VERSION "hypothesis-2026-11-23"

NS_ :

BS_:

BU_: ECU CCU TFT ABS Observer

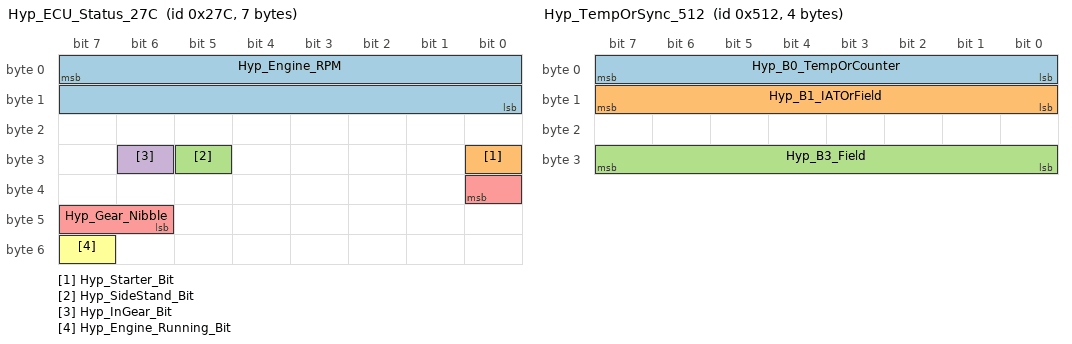
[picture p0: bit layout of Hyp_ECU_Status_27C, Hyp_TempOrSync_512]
BO_ 636 Hyp_ECU_Status_27C: 7 ECU
 SG_ Hyp_Engine_RPM : 7|16@0+ (0.4,0) [0|16000] "rpm" Observer,CCU,TFT
 SG_ Hyp_Starter_Bit : 24|1@0+ (1,0) [0|1] "" Observer
 SG_ Hyp_SideStand_Bit : 29|1@0+ (1,0) [0|1] "" Observer
 SG_ Hyp_InGear_Bit : 30|1@0+ (1,0) [0|1] "" Observer
 SG_ Hyp_Gear_Nibble : 32|3@0+ (1,0) [0|7] "" Observer,CCU,TFT
 SG_ Hyp_Engine_Running_Bit : 55|1@0+ (1,0) [0|1] "" Observer

BO_ 675 Hyp_Unknown_2A3: 8 ECU
 SG_ Hyp_Raw_2A3 : 7|64@0+ (1,0) [0|0] "" Observer

BO_ 899 Hyp_Unknown_383: 8 ECU
 SG_ Hyp_Raw_383 : 7|64@0+ (1,0) [0|0] "" Observer
 SG_ Hyp_BrakeOrFlag_Bit : 35|1@0+ (1,0) [0|1] "" Observer

BO_ 1298 Hyp_TempOrSync_512: 4 ECU
 SG_ Hyp_B0_TempOrCounter : 7|8@0+ (0.625,-30) [-40|215] "C_or_raw" Observer
 SG_ Hyp_B1_IATOrField : 15|8@0+ (0.625,-30) [-40|215] "C_or_raw" Observer
 SG_ Hyp_B3_Field : 31|8@0+ (1,0) [0|255] "" Observer

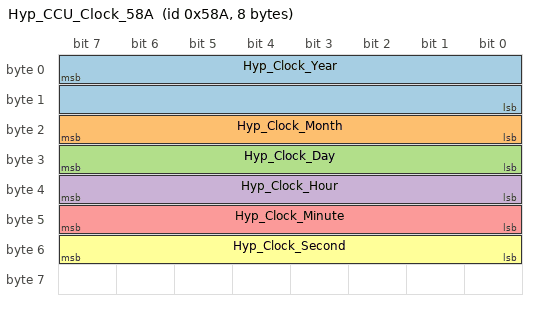
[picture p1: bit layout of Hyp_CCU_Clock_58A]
BO_ 1418 Hyp_CCU_Clock_58A: 8 CCU
 SG_ Hyp_Clock_Year : 7|16@0+ (1,0) [0|9999] "year" Observer,TFT
 SG_ Hyp_Clock_Month : 23|8@0+ (1,0) [0|12] "month" Observer,TFT
 SG_ Hyp_Clock_Day : 31|8@0+ (1,0) [0|31] "day" Observer,TFT
 SG_ Hyp_Clock_Hour : 39|8@0+ (1,0) [0|23] "h" Observer,TFT
 SG_ Hyp_Clock_Minute : 47|8@0+ (1,0) [0|59] "min" Observer,TFT
 SG_ Hyp_Clock_Second : 55|8@0+ (1,0) [0|59] "s" Observer,TFT

BO_ 1419 Hyp_CCU_Info_58B: 8 CCU
 SG_ Hyp_Raw_58B : 7|64@0+ (1,0) [0|0] "" Observer

BO_ 1425 Hyp_CCU_Phone_591: 8 CCU
 SG_ Hyp_Phone_Session : 7|8@0+ (1,0) [0|255] "" Observer,TFT

BO_ 1426 Hyp_CCU_Media_592: 8 CCU
 SG_ Hyp_Media_Status : 7|32@0+ (1,0) [0|0] "" Observer,TFT

BO_ 1428 Hyp_CCU_Notify_594: 8 CCU
 SG_ Hyp_Notify_Mask : 7|32@0+ (1,0) [0|0] "" Observer,TFT

BO_ 1429 Hyp_CCU_Notify_595: 8 CCU
 SG_ Hyp_Notify_Clear : 7|32@0+ (1,0) [0|0] "" Observer,TFT

BO_ 1434 Hyp_CCU_Navi_59A: 8 CCU
 SG_ Hyp_Text_Header : 7|64@0+ (1,0) [0|0] "" Observer,TFT

BO_ 1435 Hyp_CCU_Navi_59B: 8 CCU
 SG_ Hyp_Text_Part1 : 31|40@0+ (1,0) [0|0] "" Observer,TFT

BO_ 1436 Hyp_CCU_Navi_59C: 8 CCU
 SG_ Hyp_Text_Part2 : 15|56@0+ (1,0) [0|0] "" Observer,TFT

BO_ 1437 Hyp_CCU_UI_59D: 8 CCU
 SG_ Hyp_UI_Mode_Mask : 15|8@0+ (1,0) [0|255] "" Observer,TFT

BO_ 1438 Hyp_CCU_UI_59E: 8 CCU
 SG_ Hyp_Raw_59E : 7|64@0+ (1,0) [0|0] "" Observer,TFT

BO_ 1872 Hyp_ECU_750: 8 ECU
 SG_ Hyp_Field_B1B2 : 15|16@0+ (1,0) [0|65535] "" Observer
 SG_ Hyp_Alive_Nibble : 44|5@0+ (1,0) [0|31] "" Observer

BO_ 1873 Hyp_ECU_751: 8 ECU
 SG_ Hyp_B6_Status : 55|8@0+ (1,0) [0|255] "" Observer

BO_ 1877 Hyp_ECU_755: 8 ECU
 SG_ Hyp_B1 : 15|8@0+ (1,0) [0|255] "" Observer
 SG_ Hyp_B3 : 31|8@0+ (1,0) [0|255] "" Observer

BO_ 1878 Hyp_ECU_756: 8 ECU
 SG_ Hyp_B3 : 31|8@0+ (1,0) [0|255] "" Observer
 SG_ Hyp_B5 : 47|8@0+ (1,0) [0|255] "" Observer

BO_ 1879 Hyp_ECU_757: 8 ECU
 SG_ Hyp_B4_Flag : 32|1@0+ (1,0) [0|1] "" Observer
 SG_ Hyp_B6_Field : 49|2@0+ (1,0) [0|3] "" Observer

BO_ 1880 Hyp_ECU_758: 8 ECU
 SG_ Hyp_Maybe_TPS_Raw : 7|12@0+ (1,0) [0|4095] "" Observer
 SG_ Hyp_Maybe_APS_Raw : 47|15@0+ (1,0) [0|32767] "" Observer

BO_ 1881 Hyp_ECU_759: 8 ECU
 SG_ Hyp_Maybe_TPS_Cmd : 7|8@0+ (1,0) [0|255] "" Observer

BO_ 1889 Hyp_ABS_761: 8 ABS
 SG_ Hyp_FrontWheel_Raw : 7|16@0+ (1,0) [0|65535] "" Observer

BO_ 1890 Hyp_ABS_762: 8 ABS
 SG_ Hyp_RearWheel_Raw : 7|16@0+ (1,0) [0|65535] "" Observer

BO_ 1892 Hyp_Power_764: 8 ECU
 SG_ Hyp_Voltage_State : 7|24@0+ (1,0) [0|16777215] "" Observer

BO_ 1893 Hyp_ECU_765: 8 ECU
 SG_ Hyp_B4 : 39|8@0+ (1,0) [0|255] "" Observer

BO_ 1898 Hyp_CCU_76A: 8 CCU
 SG_ Hyp_B5_Counter : 47|8@0+ (1,0) [0|255] "" Observer

BO_ 1900 Hyp_CCU_76C: 8 CCU
 SG_ Hyp_B2_Status : 23|8@0+ (1,0) [0|255] "" Observer

BO_ 1901 Hyp_Switch_76D: 8 TFT
 SG_ Hyp_Switch_Or_Cruise_Bit : 6|1@0+ (1,0) [0|1] "" Observer

BO_ 2016 Hyp_UDS_Req_7E0: 8 CCU
 SG_ Hyp_UDS_Req_Data : 7|64@0+ (1,0) [0|0] "" Observer

BO_ 2024 Hyp_UDS_Resp_7E8: 8 ECU
 SG_ Hyp_ISO_TP_PCI : 7|8@0+ (1,0) [0|255] "" Observer
 SG_ Hyp_UDS_Resp_Payload : 15|56@0+ (1,0) [0|0] "" Observer

CM_ "ENTIRE FILE IS A HYPOTHESIS CATALOG. Not OEM ground truth. Passive signals from short listen-only captures. Road validation pending.";
CM_ BO_ 636 "HYP/OBS: RPM scale ~0.4 (~R9 100/256). Gear nibble 0=N..6, 7=between is stronger hyp (R9). Other bits weaker.";
CM_ BO_ 675 "PLACEHOLDER: nearly fixed when stopped. Meaning unknown until riding.";
CM_ BO_ 899 "HYP/CONFLICT: speed vs brake-bit (R9). Mostly fixed when stopped.";
CM_ BO_ 1298 "CONFLICT: B0/B1 often match coolant/IAT (raw*0.625-30). Old sync-counter story demoted.";
CM_ SG_ 1298 Hyp_B0_TempOrCounter "Prefer temperature hyp until proven otherwise; factor 0.625 offset -30 is R9-compatible.";
CM_ SG_ 1298 Hyp_B1_IATOrField "Same scale as B0 under temperature hyp.";
CM_ BO_ 1418 "HYP: Y-Connect clock sync. All-zero may mean unsynced.";
CM_ BO_ 1425 "HYP: phone/Y-Connect session.";
CM_ BO_ 1434 "HYP: navi/notification UTF-8 multi-frame.";
CM_ BO_ 1872 "HYP/CONFLICT: fuel-flow claim is weak; R9 points at RPM hundreds / throttle coarse.";
CM_ BO_ 1873 "HYP/CONFLICT: warmup-timer claim is weak; R9 points at neutral/clutch/stand in B6.";
CM_ BO_ 1878 "HYP/CONFLICT: injection-rate claim is weak; R9 rear wheel speed when moving.";
CM_ BO_ 1879 "HYP: lighting / high-beam candidate only.";
CM_ BO_ 1880 "HYP/CONFLICT: env-sensor claim demoted; APS/TPS (throttle) hyp is stronger from blip logs / R9.";
CM_ BO_ 1881 "HYP: commanded throttle candidate (R9).";
CM_ BO_ 1889 "PLACEHOLDER: needs road test.";
CM_ BO_ 1890 "PLACEHOLDER: needs road test.";
CM_ BO_ 2016 "OBS: UDS requests from CCU (multiple services; not a fixed 0.5s-only poll).";
CM_ BO_ 2024 "OBS: UDS responses. Fuel-counter / injector-PW byte mapping remains HYP.";

VAL_ 636 Hyp_Gear_Nibble 0 "N_or_unknown" 1 "Gear1_hyp" 2 "Gear2_hyp" 3 "Gear3_hyp" 4 "Gear4_hyp" 5 "Gear5_hyp" 6 "Gear6_hyp" 7 "Between_hyp" ;
VAL_ 636 Hyp_Starter_Bit 0 "OFF_hyp" 1 "Cranking_hyp" ;
VAL_ 636 Hyp_SideStand_Bit 0 "DOWN_hyp" 1 "UP_hyp" ;
VAL_ 636 Hyp_InGear_Bit 0 "Neutral_hyp" 1 "InGear_hyp" ;
VAL_ 636 Hyp_Engine_Running_Bit 0 "Stopped_hyp" 1 "Running_hyp" ;
VAL_ 1879 Hyp_B6_Field 0 "OFF_hyp" 3 "ON_hyp" ;
